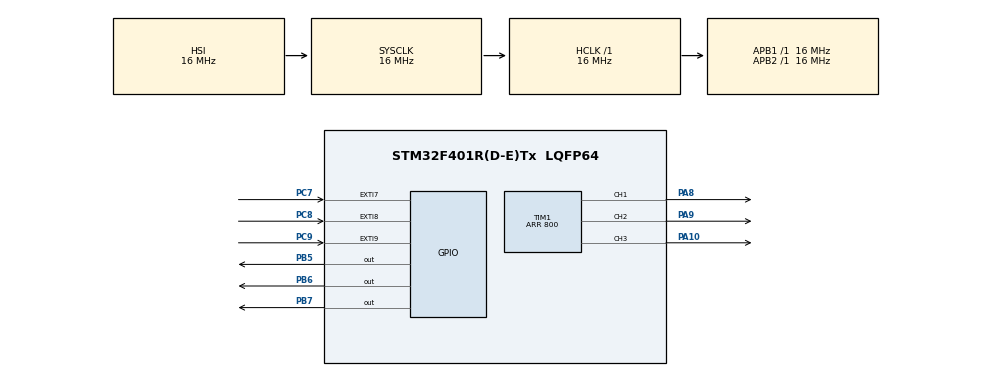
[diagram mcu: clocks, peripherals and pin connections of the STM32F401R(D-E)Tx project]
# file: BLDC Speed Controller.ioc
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Mcu.Family=STM32F4
Mcu.Name=STM32F401R(D-E)Tx
Mcu.Package=LQFP64
NVIC.EXTI9_5_IRQn=true\:0\:0\:false\:false\:true\:true\:true\:true
NVIC.PriorityGroup=NVIC_PRIORITYGROUP_4
NVIC.TIM1_UP_TIM10_IRQn=true\:0\:0\:false\:false\:true\:true\:true\:true
PA10.Signal=S_TIM1_CH3
PA8.Signal=S_TIM1_CH1
PA9.Signal=S_TIM1_CH2
PB5.Signal=GPIO_Output
PB6.Signal=GPIO_Output
PB7.Signal=GPIO_Output
PC7.GPIO_ModeDefaultEXTI=GPIO_MODE_IT_RISING_FALLING
PC7.Signal=GPXTI7
PC8.GPIO_ModeDefaultEXTI=GPIO_MODE_IT_RISING_FALLING
PC8.Signal=GPXTI8
PC9.GPIO_ModeDefaultEXTI=GPIO_MODE_IT_RISING_FALLING
PC9.Signal=GPXTI9
ProjectManager.HeapSize=0x200
ProjectManager.StackSize=0x400
ProjectManager.TargetToolchain=STM32CubeIDE
RCC.AHBFreq_Value=16000000
RCC.APB1Freq_Value=16000000
RCC.APB1TimFreq_Value=16000000
RCC.APB2Freq_Value=16000000
RCC.APB2TimFreq_Value=16000000
RCC.CortexFreq_Value=16000000
RCC.HCLKFreq_Value=16000000
RCC.HSE_VALUE=25000000
RCC.HSI_VALUE=16000000
RCC.LSE_VALUE=32768
RCC.SYSCLKFreq_VALUE=16000000
RCC.VCOOutputFreq_Value=192000000
SH.S_TIM1_CH1.0=TIM1_CH1,PWM Generation1 CH1
SH.S_TIM1_CH2.0=TIM1_CH2,PWM Generation2 CH2
SH.S_TIM1_CH3.0=TIM1_CH3,PWM Generation3 CH3
TIM1.Channel-PWM\ Generation1\ CH1=TIM_CHANNEL_1
TIM1.Channel-PWM\ Generation2\ CH2=TIM_CHANNEL_2
TIM1.Channel-PWM\ Generation3\ CH3=TIM_CHANNEL_3
TIM1.Period=800
TIM1.Pulse-PWM\ Generation1\ CH1=0
TIM1.Pulse-PWM\ Generation2\ CH2=160
VP_TIM1_VS_ClockSourceINT.Mode=Internal
board=custom

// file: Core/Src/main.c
/* USER CODE BEGIN Header */
/**
  ******************************************************************************
  * @file           : main.c
  * @brief          : Main program body
  ******************************************************************************
  * @attention
  *
  * Copyright (c) 2025 STMicroelectronics.
  * All rights reserved.
  *
  * This software is licensed under terms that can be found in the LICENSE file
  * in the root directory of this software component.
  * If no LICENSE file comes with this software, it is provided AS-IS.
  *
  ******************************************************************************
  */
/* USER CODE END Header */
#include "main.h"

TIM_HandleTypeDef htim1;

void SystemClock_Config(void);
static void MX_GPIO_Init(void);
static void MX_TIM1_Init(void);

int main(void)
{

  /* MCU Configuration--------------------------------------------------------*/

  /* Reset of all peripherals, Initializes the Flash interface and the Systick. */
  HAL_Init();

  /* Configure the system clock */
  SystemClock_Config();

  /* Initialize all configured peripherals */
  MX_GPIO_Init();
  MX_TIM1_Init();
  /* USER CODE BEGIN 2 */
  uint32_t lastPrintTime = 0;
  //used to start the motor, gets it moving so the interrupts can start firing
  /* USER CODE END 2 */

  /* Infinite loop */
  while (1)
  {
	  //code for PID here
	  uint32_t now = HAL_GetTick();
	  if (now - lastPrintTime >= 500)  // print every 500 ms
	  {
		  lastPrintTime = now;

		  // Assuming you have a printf or UART print function:
		  //printf("Speed: %.2f Hz\r\n", current_speed);
	  }
  }
}

void SystemClock_Config(void)
{
  RCC_OscInitTypeDef RCC_OscInitStruct = {0};
  RCC_ClkInitTypeDef RCC_ClkInitStruct = {0};

  /** Configure the main internal regulator output voltage
  */
  __HAL_RCC_PWR_CLK_ENABLE();
  __HAL_PWR_VOLTAGESCALING_CONFIG(PWR_REGULATOR_VOLTAGE_SCALE2);

  /** Initializes the RCC Oscillators according to the specified parameters
  * in the RCC_OscInitTypeDef structure.
  */
  RCC_OscInitStruct.OscillatorType = RCC_OSCILLATORTYPE_HSI;
  RCC_OscInitStruct.HSIState = RCC_HSI_ON;
  RCC_OscInitStruct.HSICalibrationValue = RCC_HSICALIBRATION_DEFAULT;
  RCC_OscInitStruct.PLL.PLLState = RCC_PLL_NONE;
  if (HAL_RCC_OscConfig(&RCC_OscInitStruct) != HAL_OK)
  {
    Error_Handler();
  }

  /** Initializes the CPU, AHB and APB buses clocks
  */
  RCC_ClkInitStruct.ClockType = RCC_CLOCKTYPE_HCLK|RCC_CLOCKTYPE_SYSCLK
                              |RCC_CLOCKTYPE_PCLK1|RCC_CLOCKTYPE_PCLK2;
  RCC_ClkInitStruct.SYSCLKSource = RCC_SYSCLKSOURCE_HSI;
  RCC_ClkInitStruct.AHBCLKDivider = RCC_SYSCLK_DIV1;
  RCC_ClkInitStruct.APB1CLKDivider = RCC_HCLK_DIV1;
  RCC_ClkInitStruct.APB2CLKDivider = RCC_HCLK_DIV1;

  if (HAL_RCC_ClockConfig(&RCC_ClkInitStruct, FLASH_LATENCY_0) != HAL_OK)
  {
    Error_Handler();
  }
}

static void MX_TIM1_Init(void)
{

  TIM_ClockConfigTypeDef sClockSourceConfig = {0};
  TIM_MasterConfigTypeDef sMasterConfig = {0};
  TIM_OC_InitTypeDef sConfigOC = {0};
  TIM_BreakDeadTimeConfigTypeDef sBreakDeadTimeConfig = {0};

  htim1.Instance = TIM1;
  htim1.Init.Prescaler = 0;
  htim1.Init.CounterMode = TIM_COUNTERMODE_UP;
  htim1.Init.Period = 800;
  htim1.Init.ClockDivision = TIM_CLOCKDIVISION_DIV1;
  htim1.Init.RepetitionCounter = 0;
  htim1.Init.AutoReloadPreload = TIM_AUTORELOAD_PRELOAD_DISABLE;
  if (HAL_TIM_Base_Init(&htim1) != HAL_OK)
  {
    Error_Handler();
  }
  sClockSourceConfig.ClockSource = TIM_CLOCKSOURCE_INTERNAL;
  if (HAL_TIM_ConfigClockSource(&htim1, &sClockSourceConfig) != HAL_OK)
  {
    Error_Handler();
  }
  if (HAL_TIM_PWM_Init(&htim1) != HAL_OK)
  {
    Error_Handler();
  }
  sMasterConfig.MasterOutputTrigger = TIM_TRGO_RESET;
  sMasterConfig.MasterSlaveMode = TIM_MASTERSLAVEMODE_DISABLE;
  if (HAL_TIMEx_MasterConfigSynchronization(&htim1, &sMasterConfig) != HAL_OK)
  {
    Error_Handler();
  }
  sConfigOC.OCMode = TIM_OCMODE_PWM1;
  sConfigOC.Pulse = 0;
  sConfigOC.OCPolarity = TIM_OCPOLARITY_HIGH;
  sConfigOC.OCNPolarity = TIM_OCNPOLARITY_HIGH;
  sConfigOC.OCFastMode = TIM_OCFAST_DISABLE;
  sConfigOC.OCIdleState = TIM_OCIDLESTATE_RESET;
  sConfigOC.OCNIdleState = TIM_OCNIDLESTATE_RESET;
  if (HAL_TIM_PWM_ConfigChannel(&htim1, &sConfigOC, TIM_CHANNEL_1) != HAL_OK)
  {
    Error_Handler();
  }
  sConfigOC.Pulse = 160;
  //used to start moving motors to start firing interrupts
  if (HAL_TIM_PWM_ConfigChannel(&htim1, &sConfigOC, TIM_CHANNEL_2) != HAL_OK)
  {
    Error_Handler();
  }
  sConfigOC.Pulse = 0;
  if (HAL_TIM_PWM_ConfigChannel(&htim1, &sConfigOC, TIM_CHANNEL_3) != HAL_OK)
  {
    Error_Handler();
  }
  sBreakDeadTimeConfig.OffStateRunMode = TIM_OSSR_DISABLE;
  sBreakDeadTimeConfig.OffStateIDLEMode = TIM_OSSI_DISABLE;
  sBreakDeadTimeConfig.LockLevel = TIM_LOCKLEVEL_OFF;
  sBreakDeadTimeConfig.DeadTime = 0;
  sBreakDeadTimeConfig.BreakState = TIM_BREAK_DISABLE;
  sBreakDeadTimeConfig.BreakPolarity = TIM_BREAKPOLARITY_HIGH;
  sBreakDeadTimeConfig.AutomaticOutput = TIM_AUTOMATICOUTPUT_DISABLE;
  if (HAL_TIMEx_ConfigBreakDeadTime(&htim1, &sBreakDeadTimeConfig) != HAL_OK)
  {
    Error_Handler();
  }
  HAL_TIM_MspPostInit(&htim1);

}

static void MX_GPIO_Init(void)
{
  GPIO_InitTypeDef GPIO_InitStruct = {0};

  /* GPIO Ports Clock Enable */
  __HAL_RCC_GPIOC_CLK_ENABLE();
  __HAL_RCC_GPIOA_CLK_ENABLE();
  __HAL_RCC_GPIOB_CLK_ENABLE();

  /*Configure GPIO pin Output Level */
  HAL_GPIO_WritePin(GPIOB, GPIO_PIN_5|GPIO_PIN_6|GPIO_PIN_7, GPIO_PIN_RESET);

  /*Configure GPIO pins : PC7 PC8 PC9 */
  GPIO_InitStruct.Pin = GPIO_PIN_7|GPIO_PIN_8|GPIO_PIN_9;
  GPIO_InitStruct.Mode = GPIO_MODE_IT_RISING_FALLING;
  GPIO_InitStruct.Pull = GPIO_NOPULL;
  HAL_GPIO_Init(GPIOC, &GPIO_InitStruct);

  /*Configure GPIO pins : PB5 PB6 PB7 */
  GPIO_InitStruct.Pin = GPIO_PIN_5|GPIO_PIN_6|GPIO_PIN_7;
  GPIO_InitStruct.Mode = GPIO_MODE_OUTPUT_PP;
  GPIO_InitStruct.Pull = GPIO_NOPULL;
  GPIO_InitStruct.Speed = GPIO_SPEED_FREQ_LOW;
  HAL_GPIO_Init(GPIOB, &GPIO_InitStruct);

  /* EXTI interrupt init*/
  HAL_NVIC_SetPriority(EXTI9_5_IRQn, 0, 0);
  HAL_NVIC_EnableIRQ(EXTI9_5_IRQn);

}

void Error_Handler(void)
{
  __disable_irq();
  while (1)
  {
  }
}
